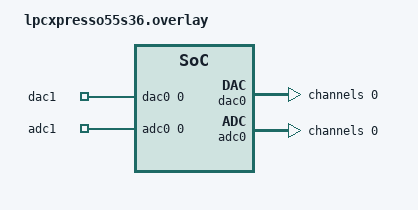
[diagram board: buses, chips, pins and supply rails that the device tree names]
/*
 * Copyright 2023 NXP
 *
 * SPDX-License-Identifier: Apache-2.0
 */

#include <zephyr/dt-bindings/adc/mcux-lpadc.h>

&dac0 {
	/* To align reference voltage with ADC. */
	voltage-reference = <1>;
};

/ {
	zephyr,user {
		io-channels = <&dac0 0 &adc0 0>;
		io-channel-names = "dac1", "adc1";
	};
};

&dac0 {
	status = "okay";

	#address-cells = <1>;
	#size-cells = <0>;

	channel@0 {
		reg = <0>;
		zephyr,resolution = <12>;
	};
};

&adc0 {
	status = "okay";

	#address-cells = <1>;
	#size-cells = <0>;

	channel@0 {
		reg = <0>;
		zephyr,gain = "ADC_GAIN_1";
		zephyr,reference = "ADC_REF_INTERNAL";
		zephyr,resolution = <12>;
		zephyr,acquisition-time = <ADC_ACQ_TIME_MAX>;
		zephyr,input-positive = <MCUX_LPADC_CH4A>;
	};
};
